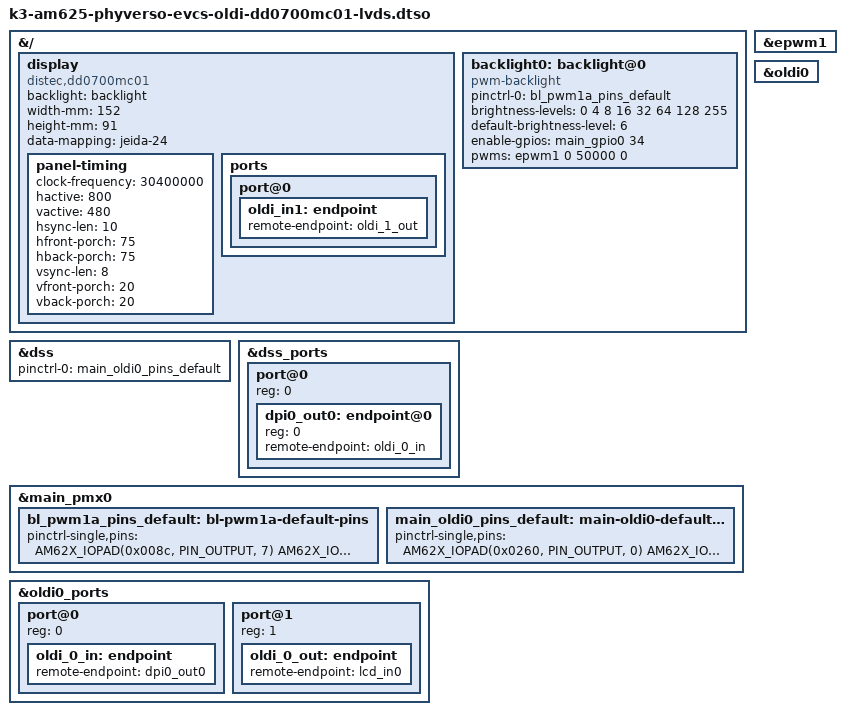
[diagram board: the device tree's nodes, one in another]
// SPDX-License-Identifier: GPL-2.0-only or MIT
/*
 * Copyright (C) 2026 PHYTEC Messtechnik GmbH
 * Author: Alexander Bauer <a.bauer@phytec.de>
 */

/dts-v1/;
/plugin/;

#include <dt-bindings/pwm/pwm.h>
#include <dt-bindings/gpio/gpio.h>
#include <dt-bindings/interrupt-controller/irq.h>
#include "k3-pinctrl.h"

&{/} {
	display: display {
		compatible = "distec,dd0700mc01", "panel-lvds";
		backlight = <&backlight>;

		width-mm = <152>;
		height-mm = <91>;

		data-mapping = "jeida-24";

		panel-timing {
			/* 800x480 */
			clock-frequency = <30400000>;
			hactive = <800>;
			vactive = <480>;
			hsync-len = <10>;
			hfront-porch = <75>;
			hback-porch = <75>;
			vsync-len = <8>;
			vfront-porch = <20>;
			vback-porch = <20>;
		};

		ports {
			#address-cells = <1>;
			#size-cells = <0>;

			port@0 {
				oldi_in1: endpoint {
					remote-endpoint = <&oldi_1_out>;
				};
			};
		};
	};

	backlight0: backlight@0 {
		pinctrl-names = "default";
		pinctrl-0 = <&bl_pwm1a_pins_default>;

		compatible = "pwm-backlight";

		brightness-levels = <0 4 8 16 32 64 128 255>;
		default-brightness-level = <6>;

		enable-gpios = <&main_gpio0 34 GPIO_ACTIVE_HIGH>;
		pwms = <&epwm1 0 50000 0>;
	};
};

&dss {
	pinctrl-names = "default";
	pinctrl-0 = <&main_oldi0_pins_default>;
	status = "okay";
};

&dss_ports {
	#address-cells = <1>;
	#size-cells = <0>;

	/* VP1: Output to OLDI */
	port@0 {
		reg = <0>;
		#address-cells = <1>;
		#size-cells = <0>;

		dpi0_out0: endpoint@0 {
			reg = <0>;
			remote-endpoint = <&oldi_0_in>;
		};
	};
};

&epwm1 {
	status = "okay";
};

&main_pmx0 {
	bl_pwm1a_pins_default: bl-pwm1a-default-pins {
		pinctrl-single,pins = <
			AM62X_IOPAD(0x008c, PIN_OUTPUT, 7) /* (L25) GPMC0_WEn.GPIO0_34 */
			AM62X_IOPAD(0x019c, PIN_OUTPUT, 6) /* (B18) MCASP0_AXR1.EHRPWM1_A */
		>;
	};

	main_oldi0_pins_default: main-oldi0-default-pins {
		pinctrl-single,pins = <
			AM62X_IOPAD(0x0260, PIN_OUTPUT, 0) /* (AA5) OLDI0_A0N */
			AM62X_IOPAD(0x025c, PIN_OUTPUT, 0) /* (Y6) OLDI0_A0P */
			AM62X_IOPAD(0x0268, PIN_OUTPUT, 0) /* (AD3) OLDI0_A1N */
			AM62X_IOPAD(0x0264, PIN_OUTPUT, 0) /* (AB4) OLDI0_A1P */
			AM62X_IOPAD(0x0270, PIN_OUTPUT, 0) /* (Y8) OLDI0_A2N */
			AM62X_IOPAD(0x026c, PIN_OUTPUT, 0) /* (AA8) OLDI0_A2P */
			AM62X_IOPAD(0x0278, PIN_OUTPUT, 0) /* (AB6) OLDI0_A3N */
			AM62X_IOPAD(0x0274, PIN_OUTPUT, 0) /* (AA7) OLDI0_A3P */
			AM62X_IOPAD(0x02a0, PIN_OUTPUT, 0) /* (AD4) OLDI0_CLK0N */
			AM62X_IOPAD(0x029c, PIN_OUTPUT, 0) /* (AE3) OLDI0_CLK0P */
		>;
	};
};

&oldi0 {
	status = "okay";
};

&oldi0_ports {
	#address-cells = <1>;
	#size-cells = <0>;

	port@0 {
		reg = <0>;
		oldi_0_in: endpoint {
			remote-endpoint = <&dpi0_out0>;
		};
	};

	port@1 {
		reg = <1>;
		oldi_0_out: endpoint {
			remote-endpoint = <&lcd_in0>;
		};
	};
};

